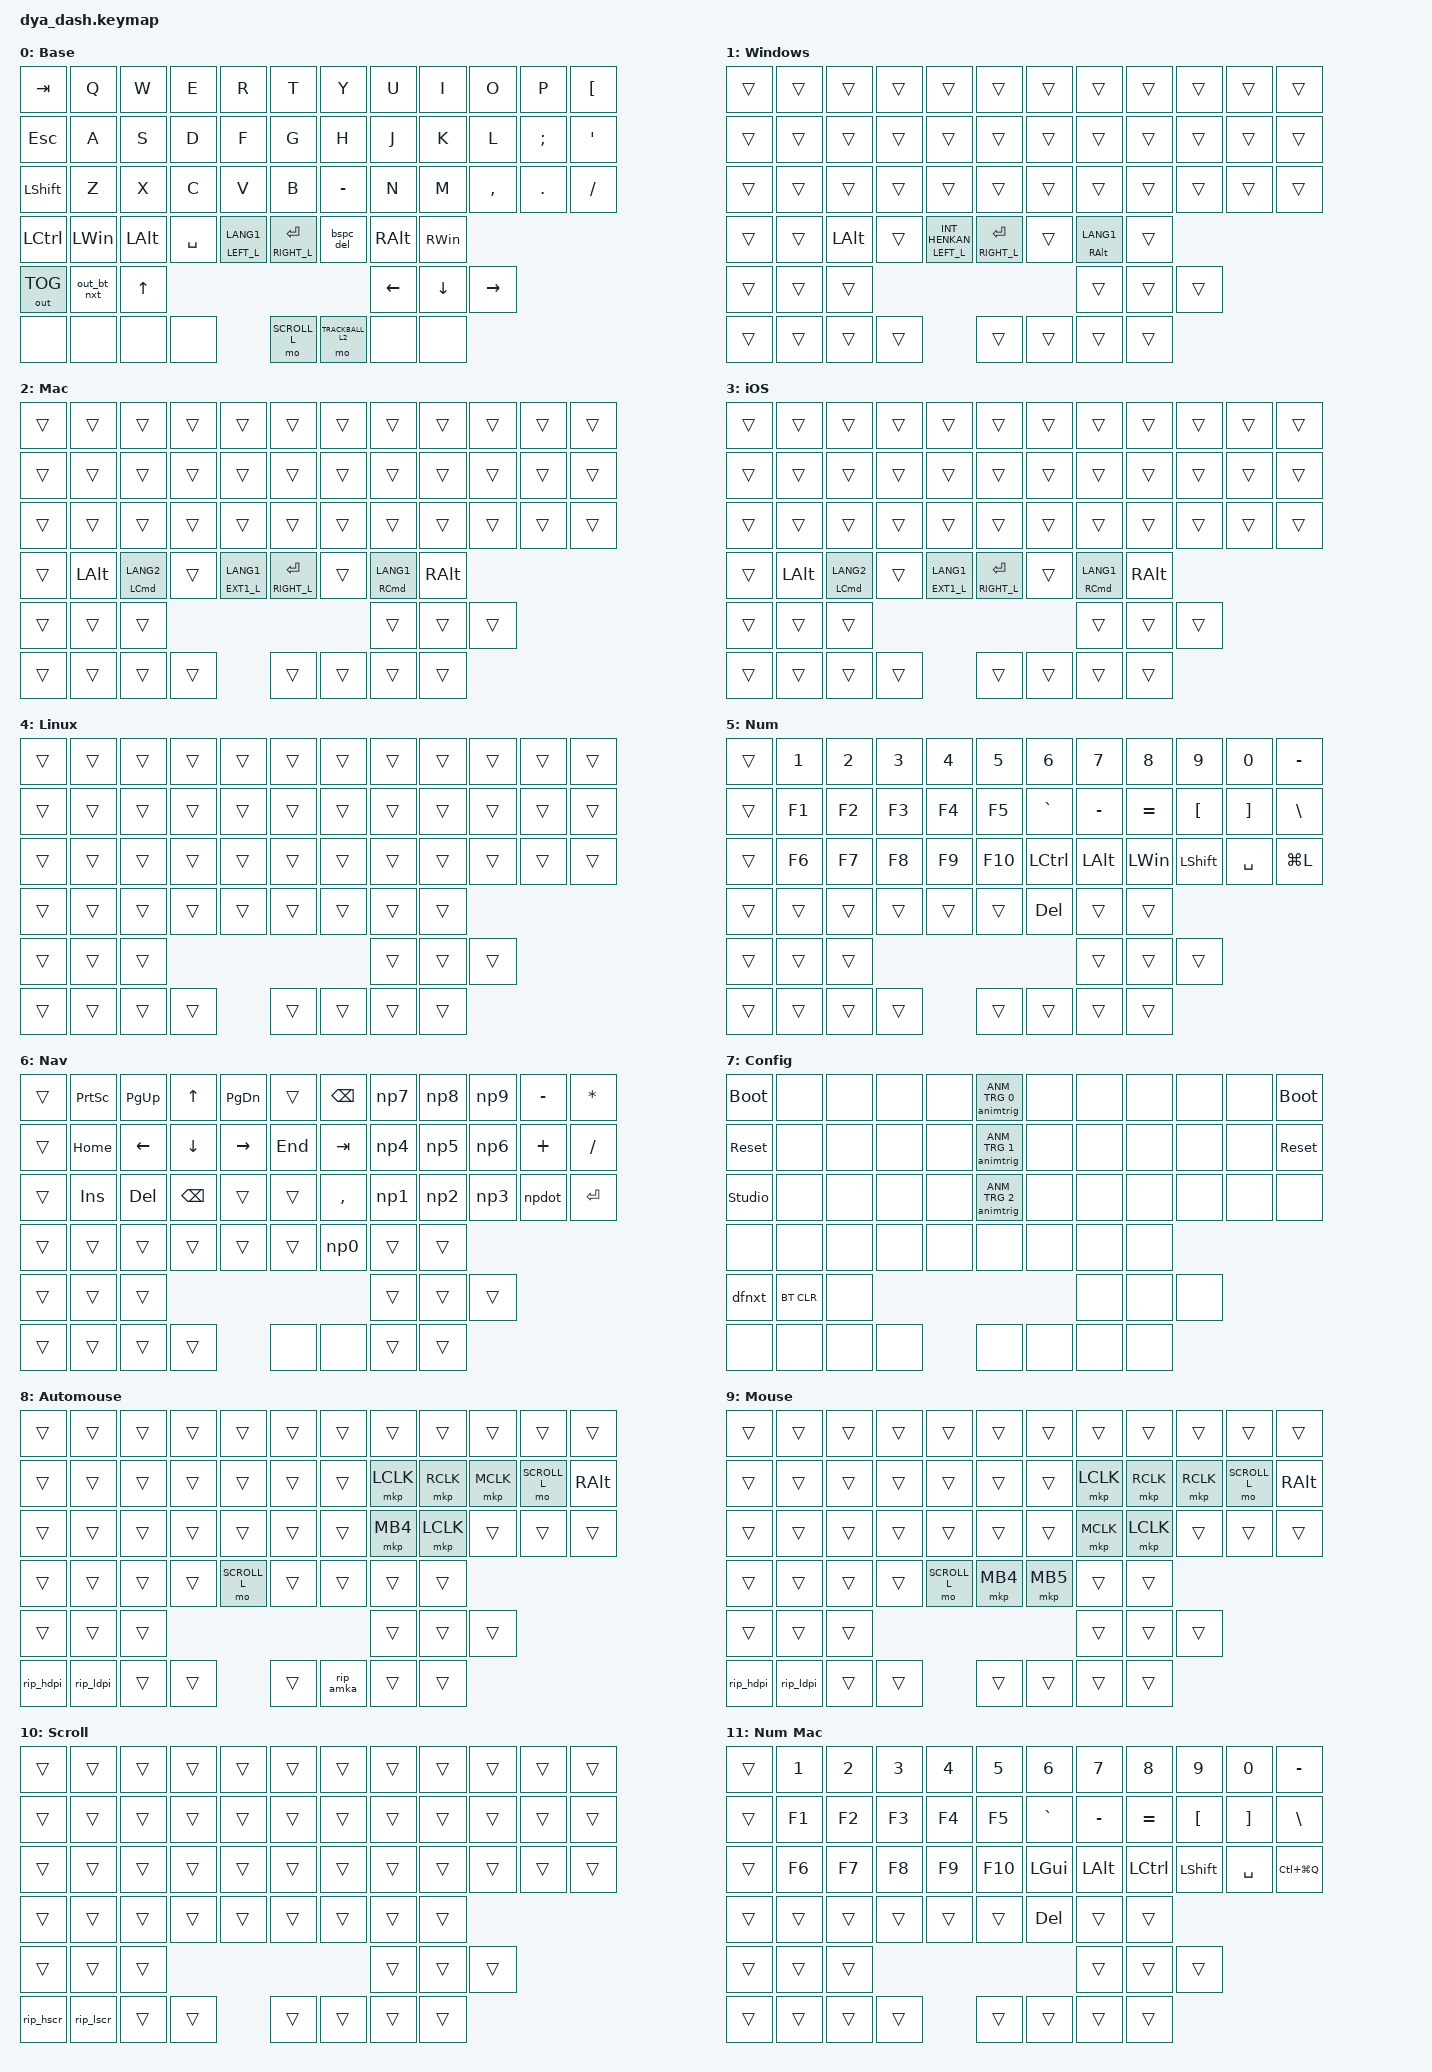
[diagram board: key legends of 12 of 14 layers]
#include <behaviors/mouse_move.dtsi>
#include <behaviors/animation_control.dtsi>
#include <behaviors/animation_trigger.dtsi>
#include <dt-bindings/zmk/mouse.h>
#include <dt-bindings/zmk_driver_animation/animation_control.h>
#include <dt-bindings/zmk_driver_animation/animation_trigger.h>
#include <dt-bindings/zmk_behavior_default_layer/default_layer.h>
#include <behaviors.dtsi>
#include <dt-bindings/zmk/bt.h>
#include <dt-bindings/zmk/keys.h>
#include <dt-bindings/zmk/outputs.h>
#include <dt-bindings/zmk/pointing.h>

#include <behaviors/runtime-input-processor.dtsi>
#include <behaviors/runtime_macro.dtsi>

// Layer definitions

#define DEFAULT_L 0
#define WINDOWS_L 1
#define MAC_L 2
#define IOS_L 3
#define LINUX_L 4
#define LEFT_L 5
#define RIGHT_L 6
#define CONFIG_L 7
#define TRACKBALL_L 8
#define TRACKBALL_L2 9
#define SCROLL_L 10
#define EXT1_L 11
#define EXT2_L 12
#define EXT3_L 13



&mouse_runtime_input_processor {
    temp-layer-enabled;
    temp-layer = <TRACKBALL_L>;
};

&mouse_runtime_input_processor_l {
    temp-layer-enabled;
    temp-layer = <TRACKBALL_L>;
};

&scroll_runtime_input_processor {
    active-layers = <BIT(SCROLL_L)>;
};

&scroll_runtime_input_processor_l {
    active-layers = <BIT(SCROLL_L)>;
};

&lt { flavor = "balanced"; quick-tap-ms = <175>; };
&mt { flavor = "balanced"; quick-tap-ms = <175>; };

&trackball_r {cpi = <600>; };
&trackball_l {cpi = <600>; };

/ {
    macros {
        // Disconnect from all once for reliable connection to selected profile.
        // ZMK automatically reconnects to current profile right after disconnection.
        out_bt_nxt: out_bt_nxt {
            compatible = "zmk,behavior-macro";
            #binding-cells = <0>;
            wait-ms = <50>;
            bindings = <&out OUT_BLE &bt BT_NXT &bt BT_DISC 0 &bt BT_DISC 1 &bt BT_DISC 2 &bt BT_DISC 3>;
        };
        // Change default layer for current profile to next layer
        dfnxt: dfnxt {
            compatible = "zmk,behavior-macro";
            #binding-cells = <0>;
            bindings = <&df DF_INC &animtrig ANM_TRG 2>;
        };
        ZMK_MACRO(nxt_win,
            display-name = "Next Window";
            bindings = <&macro_press &kp LWIN &kp LCTRL>
                     , <&macro_tap &kp RIGHT_ARROW>
                     , <&macro_release &kp LCTRL &kp LWIN>;
        )
        ZMK_MACRO(prv_win,
            display-name = "Previous Window";
            bindings = <&macro_press &kp LWIN &kp LCTRL>
                     , <&macro_tap &kp LEFT_ARROW>
                     , <&macro_release &kp LCTRL &kp LWIN>;
        )
    };
    behaviors {
        // Shift + Backspace = Delete (right outer thumb)
        bspc_del: backspace_delete {
            compatible = "zmk,behavior-mod-morph";
            #binding-cells = <0>;
            bindings = <&kp BACKSPACE>, <&kp DELETE>;
            mods = <(MOD_LSFT|MOD_RSFT)>;
        };

        // Nav layer numpad: plain = number, Shift = navigation (like a Windows numpad with Shift)
        np7: numpad_np7 {
            compatible = "zmk,behavior-mod-morph";
            #binding-cells = <0>;
            bindings = <&kp N7>, <&kp HOME>;
            mods = <(MOD_LSFT|MOD_RSFT)>;
        };
        np8: numpad_np8 {
            compatible = "zmk,behavior-mod-morph";
            #binding-cells = <0>;
            bindings = <&kp N8>, <&kp UP>;
            mods = <(MOD_LSFT|MOD_RSFT)>;
        };
        np9: numpad_np9 {
            compatible = "zmk,behavior-mod-morph";
            #binding-cells = <0>;
            bindings = <&kp N9>, <&kp PG_UP>;
            mods = <(MOD_LSFT|MOD_RSFT)>;
        };
        np4: numpad_np4 {
            compatible = "zmk,behavior-mod-morph";
            #binding-cells = <0>;
            bindings = <&kp N4>, <&kp LEFT>;
            mods = <(MOD_LSFT|MOD_RSFT)>;
        };
        np5: numpad_np5 {
            compatible = "zmk,behavior-mod-morph";
            #binding-cells = <0>;
            bindings = <&kp N5>, <&kp N5>;
            mods = <(MOD_LSFT|MOD_RSFT)>;
        };
        np6: numpad_np6 {
            compatible = "zmk,behavior-mod-morph";
            #binding-cells = <0>;
            bindings = <&kp N6>, <&kp RIGHT>;
            mods = <(MOD_LSFT|MOD_RSFT)>;
        };
        np1: numpad_np1 {
            compatible = "zmk,behavior-mod-morph";
            #binding-cells = <0>;
            bindings = <&kp N1>, <&kp END>;
            mods = <(MOD_LSFT|MOD_RSFT)>;
        };
        np2: numpad_np2 {
            compatible = "zmk,behavior-mod-morph";
            #binding-cells = <0>;
            bindings = <&kp N2>, <&kp DOWN>;
            mods = <(MOD_LSFT|MOD_RSFT)>;
        };
        np3: numpad_np3 {
            compatible = "zmk,behavior-mod-morph";
            #binding-cells = <0>;
            bindings = <&kp N3>, <&kp PG_DN>;
            mods = <(MOD_LSFT|MOD_RSFT)>;
        };
        np0: numpad_np0 {
            compatible = "zmk,behavior-mod-morph";
            #binding-cells = <0>;
            bindings = <&kp N0>, <&kp INS>;
            mods = <(MOD_LSFT|MOD_RSFT)>;
        };
        npdot: numpad_npdot {
            compatible = "zmk,behavior-mod-morph";
            #binding-cells = <0>;
            bindings = <&kp DOT>, <&kp DEL>;
            mods = <(MOD_LSFT|MOD_RSFT)>;
        };

    };

    conditional_layers {
        compatible = "zmk,conditional-layers";
        num_nav_config {
            if-layers = <LEFT_L RIGHT_L>;
            then-layer = <CONFIG_L>;
        };
        mac_num_nav_config {
            if-layers = <EXT1_L RIGHT_L>;
            then-layer = <EXT2_L>;
        };
    };

    combos {
        compatible = "zmk,combos";

        // Right side's setting button shares input pin with arrow keys.
        // It works as a combo of two arrow keys.

        setting_r1 {
            timeout-ms = <10>;
            key-positions = <47 50>;
            bindings = <&kp C_VOL_DN>;
        };

        setting_r2 {
            timeout-ms = <10>;
            key-positions = <47 49>;
            bindings = <&kp C_VOL_UP>;
        };
    };

    keymap {
        compatible = "zmk,keymap";

        // template {
            //     bindings = <
            //         &trans      &trans      &trans      &trans      &trans      &trans      /**/ &trans      &trans      &trans      &trans      &trans      &trans
            //         &trans      &trans      &trans      &trans      &trans      &trans      /**/ &trans      &trans      &trans      &trans      &trans      &trans
            //         &trans      &trans      &trans      &trans      &trans      &trans      /**/ &trans      &trans      &trans      &trans      &trans      &trans
            //                     &trans      &trans      &trans      &trans      &trans      /**/ &trans      &trans      &trans      &trans
            //
            //         &trans      &trans                                                      /**/ &trans      &trans      &trans      &trans
            //         &trans      &trans      &trans      &trans                              /**/ &trans      &trans      &trans      &trans
            //     >;
        // };

        default_layer {
            display-name = "Base";

            // --------------------------------------------------------------------------------------------------------------------------------------------------
            // |   TAB   |    Q    |    W    |    E    |    R    |    T       |            |    Y        |    U    |    I     |    O    |    P    |    [    |
            // |   ESC   |    A    |    S    |    D    |    F    |    G       |            |    H        |    J    |    K     |    L    |    ;    |    '    |
            // |  SHIFT  |    Z    |    X    |    C    |    V    |    B       |            |    -        |    N    |    M     |    ,    |    .    |    /    |
            //           |  CTRL   |   WIN   |   ALT   |  SPACE  | LEFT_LAYER |            | RIGHT_LAYER |  SPACE  |   ALT    |   WIN   |
            // --------------------------------------------------------------------------------------------------------------------------------------------------
            // | BLE     |  USB    |                                                       |  left   | up      | down    | right   |
            // | touch1  | touch2  | (touch3)  | (touch 4) |                                   | touch1  | touch2  | (touch3)  | (touch 4) |

            bindings = <
            &kp TAB                    &kp Q         &kp W     &kp E     &kp R         &kp T      &kp Y         &kp U              &kp I     &kp O      &kp P     &kp LBKT
            &kp ESC                    &kp A         &kp S     &kp D     &kp F         &kp G      &kp H         &kp J              &kp K     &kp L      &kp SEMI  &kp SQT
            &kp LSHIFT                 &kp Z         &kp X     &kp C     &kp V         &kp B      &kp MINUS     &kp N              &kp M     &kp COMMA  &kp DOT   &kp FSLH
            &kp LCTRL  &kp LWIN  &kp LALT  &kp SPACE &lt LEFT_L LANG1     &lt RIGHT_L ENTER   &bspc_del          &kp RALT  &kp RWIN
            &out OUT_TOG  &out_bt_nxt                                                    &kp UP        &kp LEFT           &kp DOWN  &kp RIGHT
            &none         &none  &none     &none                                  &mo SCROLL_L  &mo TRACKBALL_L2    &none     &none
            >;
        };

        windows_default_layer {
            display-name = "Windows";

            // Microsoft IME on a US layout ignores LANG1/LANG2: tap 23 = Henkan. 21 = plain Alt (Alt alone, Alt+Tab, Alt+F4 work).
            // Windows side: IME settings > keys: Henkan = IME-on/off (toggle).
            bindings = <
            &trans  &trans  &trans    &trans          &trans  &trans          &trans          &trans  &trans  &trans  &trans  &trans
            &trans  &trans  &trans    &trans          &trans  &trans          &trans          &trans  &trans  &trans  &trans  &trans
            &trans  &trans  &trans    &trans          &trans  &trans          &trans          &trans  &trans  &trans  &trans  &trans
            &trans  &trans    &kp LALT  &trans  &lt LEFT_L INT_HENKAN  &lt RIGHT_L ENTER  &trans  &mt RALT LANG1  &trans
            &trans  &trans                                                    &trans          &trans  &trans  &trans
            &trans  &trans  &trans    &trans                                  &trans          &trans  &trans  &trans
            >;
        };

        mac_default_layer {
            display-name = "Mac";
            bindings = <
            &trans  &trans  &trans    &trans          &trans  &trans          &trans          &trans  &trans  &trans  &trans  &trans
            &trans  &trans  &trans    &trans          &trans  &trans          &trans          &trans  &trans  &trans  &trans  &trans
            &trans  &trans  &trans    &trans          &trans  &trans          &trans          &trans  &trans  &trans  &trans  &trans
            &trans  &kp LALT  &mt LCMD LANG2  &trans  &lt EXT1_L LANG1  &lt RIGHT_L ENTER  &trans  &mt RCMD LANG1  &kp RALT
            &trans  &trans                                                    &trans          &trans  &trans  &trans
            &trans  &trans  &trans    &trans                                  &trans          &trans  &trans  &trans
            >;
        };

        ios_default_layer {
            display-name = "iOS";
            bindings = <
            &trans  &trans  &trans    &trans          &trans  &trans          &trans          &trans  &trans  &trans  &trans  &trans
            &trans  &trans  &trans    &trans          &trans  &trans          &trans          &trans  &trans  &trans  &trans  &trans
            &trans  &trans  &trans    &trans          &trans  &trans          &trans          &trans  &trans  &trans  &trans  &trans
            &trans  &kp LALT  &mt LCMD LANG2  &trans  &lt EXT1_L LANG1  &lt RIGHT_L ENTER  &trans  &mt RCMD LANG1  &kp RALT
            &trans  &trans                                                    &trans          &trans  &trans  &trans
            &trans  &trans  &trans    &trans                                  &trans          &trans  &trans  &trans
            >;
        };

        linux_default_layer {
            display-name = "Linux";
            bindings = <
            &trans  &trans  &trans  &trans  &trans  &trans  &trans  &trans  &trans  &trans  &trans  &trans
            &trans  &trans  &trans  &trans  &trans  &trans  &trans  &trans  &trans  &trans  &trans  &trans
            &trans  &trans  &trans  &trans  &trans  &trans  &trans  &trans  &trans  &trans  &trans  &trans
            &trans  &trans  &trans  &trans  &trans  &trans  &trans  &trans  &trans
            &trans  &trans                                  &trans  &trans  &trans  &trans
            &trans  &trans  &trans  &trans                  &trans  &trans  &trans  &trans
            >;
        };

        left_layer {
            display-name = "Num";

            // Numbers stay on the top row like a normal keyboard; Shift+number gives !@#$% as usual.
            // Symbols that are not on the base layer sit on the right home row; F1-F10 on the left.
            // Right bottom row = modifier row (Ctrl Alt Win Shift Space) so Ctrl+F5, Alt+F4, Win+Space work while the left thumb holds Num.
            // Outer key = screen lock (Win+L). + { } | are still Shift + = [ ] \.
            // Hold Num + Enter/Nav together = Config.
            bindings = <
            &trans   &kp N1  &kp N2  &kp N3  &kp N4  &kp N5        &kp N6     &kp N7     &kp N8     &kp N9    &kp N0    &kp MINUS
            &trans   &kp F1  &kp F2  &kp F3  &kp F4  &kp F5        &kp GRAVE  &kp MINUS  &kp EQUAL  &kp LBKT  &kp RBKT  &kp BSLH
            &trans   &kp F6  &kp F7  &kp F8  &kp F9  &kp F10       &kp LCTRL  &kp LALT   &kp LWIN   &kp LSHIFT  &kp SPACE  &kp LG(L)
            &trans    &trans  &trans    &trans    &trans        &trans     &kp DEL    &trans     &trans
            &trans   &trans                                              &trans     &trans     &trans     &trans
            &trans   &trans    &trans  &trans                            &trans     &trans     &trans     &trans
            >;
        };

        right_layer {
            display-name = "Nav";

            // Right hand = numpad (0 on the right outer thumb); Shift turns it into Home/arrows/PgUp...
            // Left hand = arrows, Home/End, PgUp/PgDn, Ins/Del/Backspace (Shift + left arrows = select).
            bindings = <
            &trans  &kp PSCRN  &kp PG_UP  &kp UP    &kp PG_DN  &trans       &kp BSPC   &np7  &np8  &np9  &kp MINUS  &kp STAR
            &trans  &kp HOME   &kp LEFT   &kp DOWN  &kp RIGHT  &kp END      &kp TAB    &np4  &np5  &np6  &kp PLUS   &kp FSLH
            &trans  &kp INS    &kp DEL    &kp BSPC  &trans     &trans       &kp COMMA  &np1  &np2  &np3  &npdot     &kp ENTER
            &trans  &trans  &trans  &trans  &trans        &trans        &np0       &trans  &trans
            &trans  &trans                                  &trans        &trans        &trans        &trans
            &trans  &trans  &trans  &trans                  &none         &none         &trans        &trans
            >;
        };

        config_layer {
            display-name = "Config";
            bindings = <
            &bootloader     &none       &none           &none  &none  &animtrig ANM_TRG 0 &none   &none   &none  &none  &none  &bootloader
            &sys_reset      &none       &none           &none  &none  &animtrig ANM_TRG 1 &none  &none    &none  &none  &none  &sys_reset
            &studio_unlock  &none       &none           &none  &none  &animtrig ANM_TRG 2 &none  &none    &none  &none  &none  &none
            &none       &none           &none  &none  &none                &none             &none             &none             &none
            &dfnxt          &bt BT_CLR                                                     &none             &none             &none             &none
            &none           &none       &none           &none                              &none             &none             &none             &none
            >;
        };

        trackball_layer {
            display-name = "Automouse";
            bindings = <
            &trans  &trans  &trans  &trans  &trans  &trans        &trans    &trans            &trans     &trans     &trans        &trans
            &trans  &trans  &trans  &trans  &trans  &trans        &trans    &mkp LCLK         &mkp RCLK  &mkp MCLK  &mo SCROLL_L  &kp RALT
            &trans  &trans  &trans  &trans  &trans  &trans        &trans    &mkp MB4         &mkp LCLK  &trans     &trans        &trans
            &trans  &trans  &trans  &trans  &mo SCROLL_L  &trans  &trans          &trans     &trans
            &trans  &trans                                        &trans    &trans            &trans     &trans
            &rip_hdpi  &rip_ldpi  &trans  &trans                        &trans    &rip_amka            &trans     &trans
            >;
        };

        trackball_layer2 {
            display-name = "Mouse";
            bindings = <
            &trans  &trans  &trans  &trans  &trans  &trans        &trans    &trans            &trans     &trans     &trans        &trans
            &trans  &trans  &trans  &trans  &trans  &trans        &trans    &mkp LCLK         &mkp RCLK  &mkp RCLK  &mo SCROLL_L  &kp RALT
            &trans  &trans  &trans  &trans  &trans  &trans        &trans    &mkp MCLK         &mkp LCLK  &trans     &trans        &trans
            &trans  &trans  &trans  &trans  &mo SCROLL_L  &mkp MB4  &mkp MB5          &trans     &trans
            &trans  &trans                                        &trans    &trans            &trans     &trans
            &rip_hdpi  &rip_ldpi  &trans  &trans                        &trans    &trans            &trans     &trans
            >;
        };

        scroll_layer {
            display-name = "Scroll";
            bindings = <
            &trans  &trans  &trans  &trans  &trans  &trans  &trans  &trans  &trans  &trans  &trans  &trans
            &trans  &trans  &trans  &trans  &trans  &trans  &trans  &trans  &trans  &trans  &trans  &trans
            &trans  &trans  &trans  &trans  &trans  &trans  &trans  &trans  &trans  &trans  &trans  &trans
            &trans  &trans  &trans  &trans  &trans  &trans  &trans  &trans  &trans
            &trans  &trans                                  &trans  &trans  &trans  &trans
            &rip_hscr  &rip_lscr &trans  &trans                  &trans  &trans  &trans  &trans
            >;
        };

        extra1 {
            display-name = "Num Mac";

            // Same as Num, but the right bottom modifier row is Cmd Option Control Shift Space, outer key = screen lock (Ctrl+Cmd+Q) (used from the Mac/iOS layers).
            bindings = <
            &trans   &kp N1  &kp N2  &kp N3  &kp N4  &kp N5        &kp N6     &kp N7     &kp N8     &kp N9    &kp N0    &kp MINUS
            &trans   &kp F1  &kp F2  &kp F3  &kp F4  &kp F5        &kp GRAVE  &kp MINUS  &kp EQUAL  &kp LBKT  &kp RBKT  &kp BSLH
            &trans   &kp F6  &kp F7  &kp F8  &kp F9  &kp F10       &kp LGUI   &kp LALT   &kp LCTRL  &kp LSHIFT  &kp SPACE  &kp LC(LG(Q))
            &trans    &trans  &trans    &trans    &trans        &trans     &kp DEL    &trans     &trans
            &trans   &trans                                              &trans     &trans     &trans     &trans
            &trans   &trans    &trans  &trans                            &trans     &trans     &trans     &trans
            >;
        };

        extra2 {
            display-name = "Config Mac";

            // Copy of Config for Mac/iOS (Num Mac + Nav). Must sit above Num Mac (Ext1) so nothing is hidden.
            bindings = <
            &bootloader     &none       &none           &none  &none  &animtrig ANM_TRG 0 &none   &none   &none  &none  &none  &bootloader
            &sys_reset      &none       &none           &none  &none  &animtrig ANM_TRG 1 &none  &none    &none  &none  &none  &sys_reset
            &studio_unlock  &none       &none           &none  &none  &animtrig ANM_TRG 2 &none  &none    &none  &none  &none  &none
            &none       &none           &none  &none  &none                &none             &none             &none             &none
            &dfnxt          &bt BT_CLR                                                     &none             &none             &none             &none
            &none           &none       &none           &none                              &none             &none             &none             &none
            >;
        };

        extra3 {
            display-name = "Ext3";
            bindings = <
            &trans  &trans  &trans  &trans  &trans  &trans  &trans  &trans  &trans  &trans  &trans  &trans
            &trans  &trans  &trans  &trans  &trans  &trans  &trans  &trans  &trans  &trans  &trans  &trans
            &trans  &trans  &trans  &trans  &trans  &trans  &trans  &trans  &trans  &trans  &trans  &trans
            &trans  &trans  &trans  &trans  &trans  &trans  &trans  &trans  &trans
            &trans  &trans                                  &trans  &trans  &trans  &trans
            &trans  &trans  &trans  &trans                  &trans  &trans  &trans  &trans
            >;
        };
    };
};
